# EFM32GG11B840F1024GL192 register map
File version: 4.0.0
CPU: CM4 r0p1, little endian, MPU, FPU, 3 interrupt priority bits
Registers are 32-bit, read-write, reset 0x0 unless marked. A register's access mark holds for its fields unless they carry their own. Offsets are from the block's base; [hi:lo] are bit positions; {n}, {i} and the like mark numbered series; 'fields as' and 'values as' point back to an identical list.

## SDIO
Base 0x400F1000
0x00 SDMASYSADDR — SDMA System Address Register
  [31:0] SDMASYSADDRARG — Physical SYS Memory ADDR Used for DMA Transfers or the Second Argument for the Auto CMD23
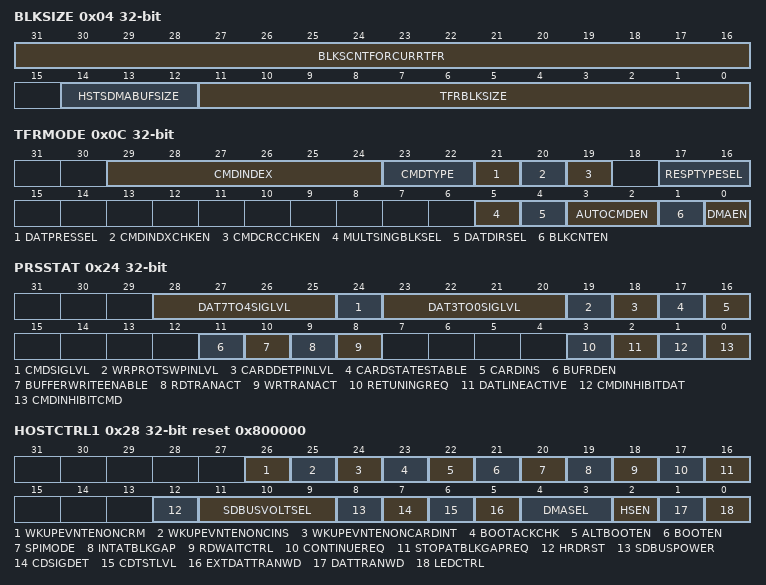
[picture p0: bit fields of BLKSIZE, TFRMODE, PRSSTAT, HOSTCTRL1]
0x04 BLKSIZE — Block Size and Block Count Register
  [31:16] BLKSCNTFORCURRTFR — Blocks Count for Current Transfer
    0=STOPCNT
  [14:12] HSTSDMABUFSIZE — Host SDMA Buffer Size
    0=SIZE4 (4KB(Detects A11 Carry out)); 1=SIZE8 (8KB(Detects A12 Carry out)); 2=SIZE16 (16KB(Detects A13 Carry out)); 3=SIZE32 (32KB(Detects A14 Carry out)); 4=SIZE64 (64KB(Detects A15 Carry out)); 5=SIZE128 (128KB(Detects A16 Carry out)); 6=SIZE256 (256KB(Detects A17 Carry out)); 7=SIZE512 (512KB(Detects A18 Carry out))
  [11:0] TFRBLKSIZE — Transfer Block Size, Specifies the Block Size for Block Data Transfers for CMD17, CMD18, CMD24, CMD25, and CMD53
    0=NOXFER
0x08 CMDARG1 — SD Command Argument Register
  [31:0] CMDARG1 — Command Argument 1
0x0C TFRMODE — Transfer Mode and Command Register
  [29:24] CMDINDEX — Command Index
  [23:22] CMDTYPE — Command Type
    0=NORMAL (Normal Command); 1=SUSPEND (Suspend command); 2=RESUME (Resume command); 3=ABORT (Abort command)
  [21] DATPRESSEL — Data Present Select
  [20] CMDINDXCHKEN — Command Index Check Enable
  [19] CMDCRCCHKEN — Command CRC Check Enable
  [17:16] RESPTYPESEL — Response Type Select
    0=NORESP; 1=RESP136 (RESP Length 136); 2=RESP48 (RESP Length 48); 3=BUSYAFTRESP (RESP Length 48 check busy after RESP)
  [5] MULTSINGBLKSEL — Multiple or Single Block Data Transfer Selection
  [4] DATDIRSEL — Data Transfer Direction Select
  [3:2] AUTOCMDEN — Auto Command Enable
    0=ACMDDISABLED (Auto CMD Disabled); 1=ACMD12EN (Auto CMD12 Enable); 2=ACMD23EN (Auto CMD23 Enable)
  [1] BLKCNTEN — Block Count Enable
  [0] DMAEN — DMA Enable
0x10 RESP0 ro — Response0 and Response1 Register
  [31:0] CMDRESP0 — Command Response 0
0x14 RESP2 ro — Response2 and Response3 Register
  [31:0] CMDRESP1 — Command Response 1
0x18 RESP4 ro — Response4 and Response5 Register
  [31:0] CMDRESP2 — Command Response 2
0x1C RESP6 ro — Response6 and Response7 Register
  [31:0] CMDRESP3 — Command Response 3
0x20 BUFDATPORT — Buffer Data Register
  [31:0] BUFDAT — Buffer Data
0x24 PRSSTAT ro — Present State Register
  [28:25] DAT7TO4SIGLVL — DAT[7:4] Line Signal Level
  [24] CMDSIGLVL — Command Line Signal Level
  [23:20] DAT3TO0SIGLVL — DAT[3:0] Line Signal Level
  [19] WRPROTSWPINLVL — Write Protect Switch Pin Level
  [18] CARDDETPINLVL — Card Detect Pin Level
  [17] CARDSTATESTABLE — Card State Stable Status
  [16] CARDINS — Card Inserted Status
  [11] BUFRDEN — Buffer Read Enable
  [10] BUFFERWRITEENABLE
  [9] RDTRANACT — Read Transfer Active
  [8] WRTRANACT — Write Transfer Active
  [3] RETUNINGREQ — Re-Tuning Request
  [2] DATLINEACTIVE
  [1] CMDINHIBITDAT — Command Inhibit (DAT)
  [0] CMDINHIBITCMD — Command Inhibit (CMD)
0x28 HOSTCTRL1 reset 0x800000 — Host Control1, Power, Block Gap and Wakeup-up Control Register
  [26] WKUPEVNTENONCRM — Wakeup Event Enable on SD Card Removal
  [25] WKUPEVNTENONCINS — Wakeup Event Enable on SD Card Insertion
  [24] WKUPEVNTENONCARDINT — Wakeup Event Enable on Card Interrupt
  [23] BOOTACKCHK — Boot Ack Check
  [22] ALTBOOTEN — Alternate Boot Enable
  [21] BOOTEN — Boot Enable
  [20] SPIMODE — SPI Mode Enable
  [19] INTATBLKGAP — Interrupt at Block Gap
  [18] RDWAITCTRL — Read Wait Control
  [17] CONTINUEREQ — Continue Request
  [16] STOPATBLKGAPREQ — Stop at Block Gap Request
  [12] HRDRST — Hardware Reset Signal
  [11:9] SDBUSVOLTSEL — SD Bus Voltage Select
    5=1P8V (Select 1.8V); 6=3P0V (Select 3.0V); 7=3P3V (Select 3.3V)
  [8] SDBUSPOWER
  [7] CDSIGDET — Card Detetct Signal Detection
  [6] CDTSTLVL — Card Detect Test Level
  [5] EXTDATTRANWD — Extended Data Transfer Width
  [4:3] DMASEL — DMA Select
    0=SDMA (SDMA selected); 1=ADMA1 (32-bit ADMA1 selected); 2=ADMA2 (32-bit ADMA2 selected); 3=64BITADMA2 (64-bit ADMA2 selected)
  [2] HSEN — High Speed Enable
  [1] DATTRANWD — Data Transfer Width 1-bit or 4-bit Mode
  [0] LEDCTRL — LED Control
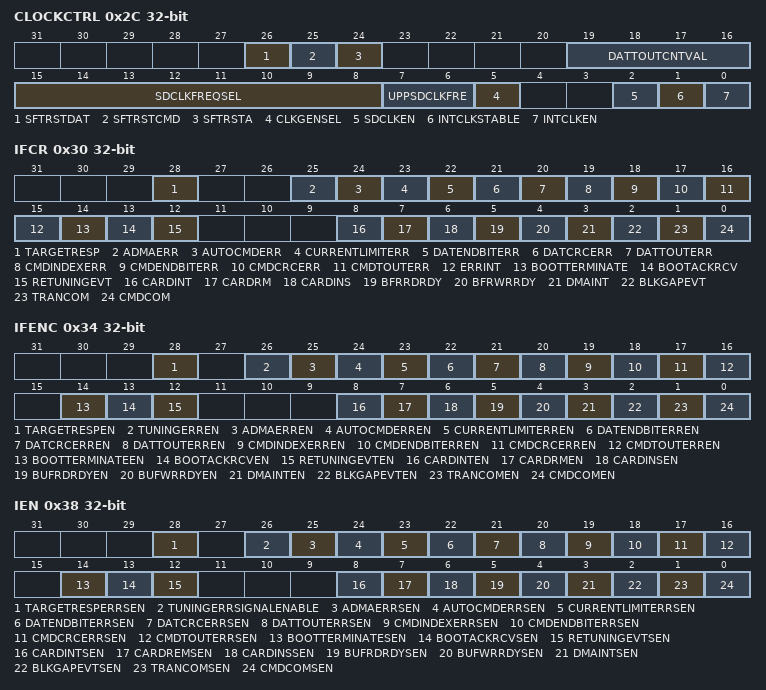
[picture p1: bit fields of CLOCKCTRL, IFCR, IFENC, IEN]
0x2C CLOCKCTRL — Clock Control, Timeout Control and Software Register
  [26] SFTRSTDAT — Software Reset for DAT Line
  [25] SFTRSTCMD — Software Reset for CMD Line
  [24] SFTRSTA — Software Reset for All
  [19:16] DATTOUTCNTVAL — Data Timeout Counter Value
  [15:8] SDCLKFREQSEL — SD_CLK Frequency Select
    0=NODIVISION
  [7:6] UPPSDCLKFRE — Upper Bits of SD_CLK Frequency Select
  [5] CLKGENSEL — Clock Generator Select
  [2] SDCLKEN — SDIO_CLK Pin Clock Enable
  [1] INTCLKSTABLE ro — Internal Clock Stable
  [0] INTCLKEN — Internal Clock Enable
0x30 IFCR — Normal and Error Interrupt Status Register
  [28] TARGETRESP — Specific Error STAT
  [25] ADMAERR — ADMA Error
  [24] AUTOCMDERR — Auto CMD Error
  [23] CURRENTLIMITERR — Current Limit Error
  [22] DATENDBITERR — Data End Bit Error
  [21] DATCRCERR — Data CRC Error
  [20] DATTOUTERR — Data Time-out Error
  [19] CMDINDEXERR — Command Index Error
  [18] CMDENDBITERR — Command End Bit Error
  [17] CMDCRCERR — CMD CRC Error
  [16] CMDTOUTERR — Command Timeout Error
  [15] ERRINT ro — Error Interrupt
  [14] BOOTTERMINATE — Boot Terminate Interrupt
  [13] BOOTACKRCV — Boot Ack Received
  [12] RETUNINGEVT ro — Re-Tunning Event
  [8] CARDINT ro — Card Interrupt
  [7] CARDRM — Card Removal
  [6] CARDINS — Card Insertion
  [5] BFRRDRDY — Buffer Read Ready
  [4] BFRWRRDY — Buffer Write Ready
  [3] DMAINT — DMA Interrupt
  [2] BLKGAPEVT — Block Gap Event
  [1] TRANCOM — Transfer Complete
  [0] CMDCOM — Command Complete
0x34 IFENC — Normal and Error Interrupt Status Enable Register
  [28] TARGETRESPEN — Target Response/Host Error Status Enable
  [26] TUNINGERREN — Tuning Error Status Enable
  [25] ADMAERREN — ADMA Error Status Enable
  [24] AUTOCMDERREN — Auto CMD12 Error Status Enable
  [23] CURRENTLIMITERREN — Current Limit Error Status Enable
  [22] DATENDBITERREN — Data End Bit Error Status Enable
  [21] DATCRCERREN — Data CRC Error Status Enable
  [20] DATTOUTERREN — Data Timeout Error Status Enable
  [19] CMDINDEXERREN — Command Index Error Status Enable
  [18] CMDENDBITERREN — Command End Bit Error Status Enable
  [17] CMDCRCERREN — Command CRC Error Status Enable
  [16] CMDTOUTERREN — Command Time-out Error Status Enable
  [14] BOOTTERMINATEEN — Boot Terminate Interrupt Signal Enable
  [13] BOOTACKRCVEN — Boot Ack Received Signal Enable
  [12] RETUNINGEVTEN — Re-Tunning Event Signal Enable
  [8] CARDINTEN — Card Interrupt Signal Enable
  [7] CARDRMEN — Card Removal Signal Enable
  [6] CARDINSEN — Card Insertion Signal Enable
  [5] BUFRDRDYEN — Buffer Read Ready Signal Enable
  [4] BUFWRRDYEN — Buffer Write Ready Signal Enable
  [3] DMAINTEN — DMA Interrupt Signal Enable
  [2] BLKGAPEVTEN — Block Gap Event Signal Enable
  [1] TRANCOMEN — Transfer Complete Signal Enable
  [0] CMDCOMEN — Command Complete Signal Enable
0x38 IEN — Normal and Error Interrupt Signal Enable Register
  [28] TARGETRESPERRSEN — Target Response Error Signal Enable
  [26] TUNINGERRSIGNALENABLE — Tuning Error Signal Enable
  [25] ADMAERRSEN — ADMA Error Signal Enable
  [24] AUTOCMDERRSEN — Auto CMD12 Error Signal Enable
  [23] CURRENTLIMITERRSEN — Current Limit Error Signal Enable
  [22] DATENDBITERRSEN — Data End Bit Error Signal Enable
  [21] DATCRCERRSEN — Data CRC Error Signal Enable
  [20] DATTOUTERRSEN — Data Timeout Error Signal Enable
  [19] CMDINDEXERRSEN — Command Index Error Signal Enable
  [18] CMDENDBITERRSEN — Command End Bit Error Signal Enable
  [17] CMDCRCERRSEN — Command CRC Error Signal Enable
  [16] CMDTOUTERRSEN — Command Timeout Error Signal Enable
  [14] BOOTTERMINATESEN — Boot Terminate Interrupt Signal Enable
  [13] BOOTACKRCVSEN — Boot Ack Received Signal Enable
  [12] RETUNINGEVTSEN — Re-Tuning Event Signal Enable
  [8] CARDINTSEN — Card Interrupt Signal Enable
  [7] CARDREMSEN — Card Removal Signal Enable
  [6] CARDINSSEN — Card Insertion Signal Enable
  [5] BUFRDRDYSEN — Buffer Read Ready Signal Enable
  [4] BUFWRRDYSEN — Buffer Write Ready Signal Enable
  [3] DMAINTSEN — DMA Interrupt Signal Enable
  [2] BLKGAPEVTSEN — Block Gap Event Signal Enable
  [1] TRANCOMSEN — Transfer Complete Signal Enable
  [0] CMDCOMSEN — Command Complete Signal Enable
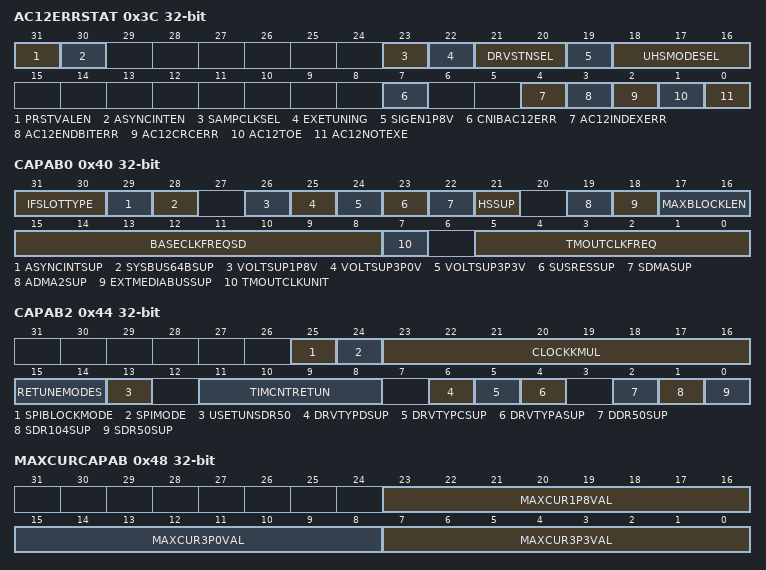
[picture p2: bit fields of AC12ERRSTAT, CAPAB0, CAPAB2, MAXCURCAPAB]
0x3C AC12ERRSTAT — AUTO CMD12 Error Status and Host Control2 Register
  [31] PRSTVALEN — Preset Value Enable
  [30] ASYNCINTEN — Asynchronous Interrupt Enable
  [23] SAMPCLKSEL — Sampling Clock Select
  [22] EXETUNING — Execute Tuning
  [21:20] DRVSTNSEL — Driver Strength Select
    0=TYPEB (Driver Type B is selected (Default)); 1=TYPEA (Driver Type A is selected); 2=TYPEC (Driver Type C is selected); 3=TYPED (Driver Type D is selected)
  [19] SIGEN1P8V — Voltage 1.8V Signal Enable
  [18:16] UHSMODESEL — UHS Mode Select
    0=SDR12; 1=SDR25; 2=SDR50; 3=SDR104; 4=DDR50
  [7] CNIBAC12ERR ro — Command Not Issued By Auto CMD12 Error
  [4] AC12INDEXERR ro — Auto CMD Index Error
  [3] AC12ENDBITERR ro — Auto CMD End Bit Error
  [2] AC12CRCERR ro — Auto CMD CRC Error
  [1] AC12TOE ro — Auto CMD12 Timeout Error
  [0] AC12NOTEXE ro — Auto CMD12 Not Executed
0x40 CAPAB0 ro — Capabilities Register to Hold Bits 31~0
  [31:30] IFSLOTTYPE — Interface Card Slot Type
    0=REMOVABLE (Removable Card Slot); 1=EMBEDDED (Only one non-removable device is conected to a SD bus slot); 2=SHARED (Can be set if Host controller supports Shared Bus CTRL register)
  [29] ASYNCINTSUP — Asynchronous Interrupt Support
  [28] SYSBUS64BSUP — System Bus 64-bit Support
  [26] VOLTSUP1P8V — Voltage Support 1.8V
  [25] VOLTSUP3P0V — Voltage Support 3.0V
  [24] VOLTSUP3P3V — Voltage Support 3.3V
  [23] SUSRESSUP — Suspend / Resume Support
  [22] SDMASUP — SDMA Support
  [21] HSSUP — High Speed Support
  [19] ADMA2SUP — ADMA2 Support
  [18] EXTMEDIABUSSUP — Extended Media Bus Support
  [17:16] MAXBLOCKLEN — Maximum Block Length
  [15:8] BASECLKFREQSD — Base Clock Frequency for SD_CLK
  [7] TMOUTCLKUNIT — Timeout Clock Unit
  [5:0] TMOUTCLKFREQ — Timeout Clock Frequency
0x44 CAPAB2 ro — Capabilities Register to Hold Bits 63~32
  [25] SPIBLOCKMODE — SPI Block Mode Support
  [24] SPIMODE — SPI Mode Support
  [23:16] CLOCKKMUL — Clock Multiplier
  [15:14] RETUNEMODES — Re-tuning Modes
  [13] USETUNSDR50 — Use Tuning for SDR50
  [11:8] TIMCNTRETUN — Timer Count for Re-Tuning
  [6] DRVTYPDSUP — Driver Type D Support
  [5] DRVTYPCSUP — Driver Type C Support
  [4] DRVTYPASUP — Driver Type a Support
  [2] DDR50SUP — DDR50 Support
  [1] SDR104SUP — SDR104 Support
  [0] SDR50SUP — SDR50 Support
0x48 MAXCURCAPAB ro — Maximum Current Capabilities Register
  [23:16] MAXCUR1P8VAL — Maximum Current for 1.8V
  [15:8] MAXCUR3P0VAL — Maximum Current for 3.0V
  [7:0] MAXCUR3P3VAL — Maximum Current for 3.3V
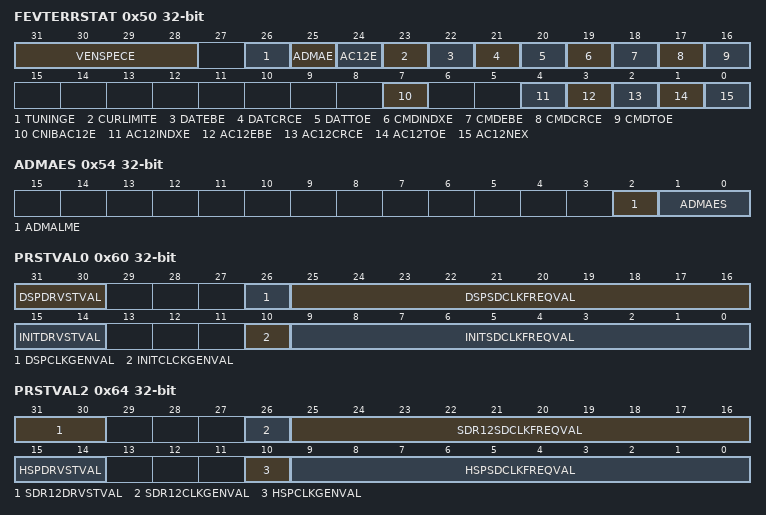
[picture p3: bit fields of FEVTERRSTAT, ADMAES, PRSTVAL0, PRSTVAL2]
0x50 FEVTERRSTAT — Force Event Register for Auto CMD Error Status
  [31:28] VENSPECE ro — Force Event for Vendox Specific Error Status
  [26] TUNINGE ro — Force Event for Tuning Errro
  [25] ADMAE — Force Event for ADMA Error
  [24] AC12E — Force Event for Auto CMD Error
  [23] CURLIMITE — Force Event for Current Limit Error
  [22] DATEBE — Force Event for Data End Bit Error
  [21] DATCRCE — Force Event for Data CRC Error
  [20] DATTOE — Force Event for Data Timeout Error
  [19] CMDINDXE — Force Event for Command Index Error
  [18] CMDEBE — Force Event for Command End Bit Error
  [17] CMDCRCE — Force Event for Command CRC Error
  [16] CMDTOE — Force Event for Command Timeout Error
  [7] CNIBAC12E — Force Event for Command Not Issued By Auto CMD12 Error
  [4] AC12INDXE — Force Event for Auto CMD Index Error
  [3] AC12EBE — Force Event for Auto CMD End Bit Error
  [2] AC12CRCE — Force Event for Auto CMD CRC Error
  [1] AC12TOE — Force Event for Auto CMD Timeout Error
  [0] AC12NEX — Force Event for Command Not Issued By Auto CM12 Not Executed
0x54 ADMAES ro — ADMA Error Status Register
  [2] ADMALME — ADMA Length Mismatch Error
  [1:0] ADMAES — ADMA Error State
0x58 ADSADDR — ADMA System Address Register
  [31:0] ADSADDR — ADMA System Address
0x60 PRSTVAL0 ro — Preset Value for Initialization and Default Speed Mode
  [31:30] DSPDRVSTVAL — Driver Strength Select Value for Default Speed
    values as AC12ERRSTAT.DRVSTNSEL
  [26] DSPCLKGENVAL — Clock Generator Select Value for Default Speed
  [25:16] DSPSDCLKFREQVAL — SD_CLK Frequency Select Value for Default Speed
  [15:14] INITDRVSTVAL — Driver Strength Select Value for Initialization
    values as AC12ERRSTAT.DRVSTNSEL
  [10] INITCLCKGENVAL — Clock Generator Select Value for Initialization
  [9:0] INITSDCLKFREQVAL — SD_CLK Frequency Select Value for Initialization
0x64 PRSTVAL2 ro — Preset Value for High Speed and SDR12 Modes
  [31:30] SDR12DRVSTVAL — Driver Strength Select Value for SDR12
    values as AC12ERRSTAT.DRVSTNSEL
  [26] SDR12CLKGENVAL — Clock Generator Select Value for SDR12
  [25:16] SDR12SDCLKFREQVAL — SD_CLK Frequency Select Value for SDR12
  [15:14] HSPDRVSTVAL — Driver Strength Select Value for High Speed
    values as AC12ERRSTAT.DRVSTNSEL
  [10] HSPCLKGENVAL — Clock Generator Select Value for High Speed
  [9:0] HSPSDCLKFREQVAL — SD_CLK Frequency Select Value for High Speed
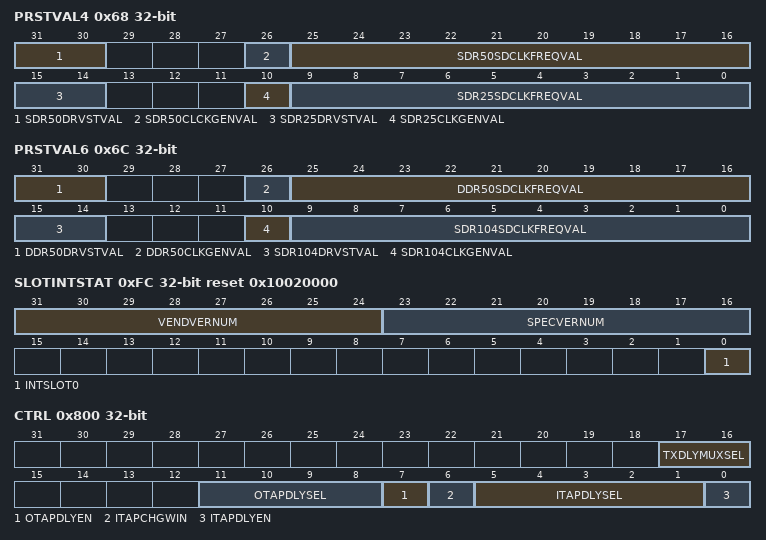
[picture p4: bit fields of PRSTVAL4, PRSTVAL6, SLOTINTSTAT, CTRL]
0x68 PRSTVAL4 ro — Preset Value for SDR25 and SDR50 Modes
  [31:30] SDR50DRVSTVAL — Driver Strength Select Value for SDR50
    values as AC12ERRSTAT.DRVSTNSEL
  [26] SDR50CLCKGENVAL — Clock Generator Select Value for SDR50
  [25:16] SDR50SDCLKFREQVAL — SD_CLK Frequency Select Value for SDR50
  [15:14] SDR25DRVSTVAL — Driver Strength Select Value for SDR25
    values as AC12ERRSTAT.DRVSTNSEL
  [10] SDR25CLKGENVAL — Clock Generator Select Value for SDR25
  [9:0] SDR25SDCLKFREQVAL — SD_CLK Frequency Select Value for SDR25
0x6C PRSTVAL6 ro — Preset Value for SDR104 and DDR50 Modes
  [31:30] DDR50DRVSTVAL — Driver Strength Select Value for DDR50
    values as AC12ERRSTAT.DRVSTNSEL
  [26] DDR50CLKGENVAL — Clock Generator Select Value for DDR50
  [25:16] DDR50SDCLKFREQVAL — SD_CLK Frequency Select Value for DDR50
  [15:14] SDR104DRVSTVAL — Driver Strength Select Value for SDR104
    values as AC12ERRSTAT.DRVSTNSEL
  [10] SDR104CLKGENVAL — Clock Generator Select Value for SDR104
  [9:0] SDR104SDCLKFREQVAL — SD_CLK Frequency Select Value for SDR104
0x70 BOOTTOCTRL — Boot Timeout Control Register
  [31:0] BOOTDATTOCNT — Boot Data Timeout Counter Value
0xFC SLOTINTSTAT ro reset 0x10020000 — Slot Interrupt Status Register
  [31:24] VENDVERNUM — Vendor Version Number
  [23:16] SPECVERNUM — Host Controller Compliant Spec Version Number
  [0] INTSLOT0 — Interrupt Signal for Slot#0
0x800 CTRL — Core Control Signals
  [17:16] TXDLYMUXSEL — TX Delay Mux Selection
  [11:8] OTAPDLYSEL — Selects One of 32 Taps on the SDIO_CLK Pin
  [7] OTAPDLYEN — Selective Tap Delay Line Enable on SDIO_CLK Pin
  [6] ITAPCHGWIN — Gating Signal for Tap Delay Change
  [5:1] ITAPDLYSEL — Selects One of 32 Taps on the Rxclk_in Line
  [0] ITAPDLYEN — Selective Tap Delay Line Enable on Rxclk_in
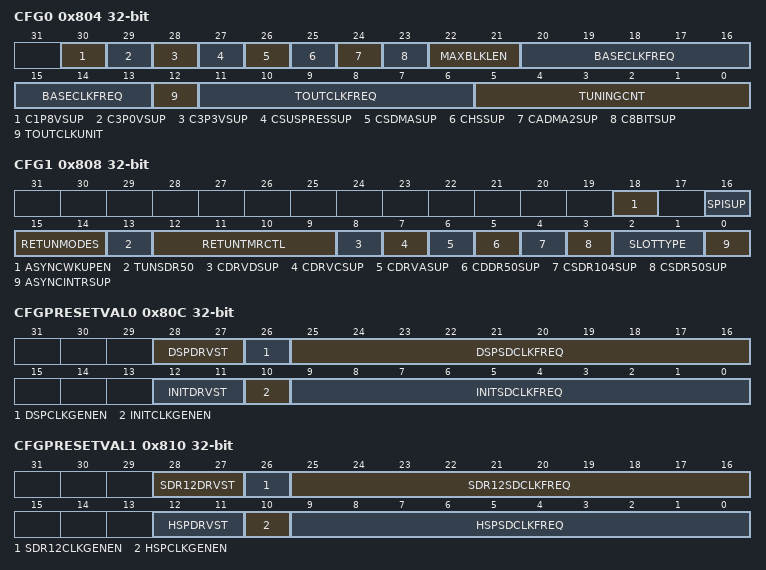
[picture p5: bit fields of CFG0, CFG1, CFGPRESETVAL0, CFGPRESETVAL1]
0x804 CFG0 — Core Configuration 0
  [30] C1P8VSUP — 1P8V Support
  [29] C3P0VSUP — 3P0V Support
  [28] C3P3VSUP — Core 3P3V Support
  [27] CSUSPRESSUP — Suspend/Resume Support
  [26] CSDMASUP — SDMA Mode Support
  [25] CHSSUP — High Speed Mode Support
  [24] CADMA2SUP — ADMA2 Mode Support
  [23] C8BITSUP — 8-bit Interface Support
  [22:21] MAXBLKLEN — MAX Block Length of Transfer
    0=512B (512 Bytes are Selected); 1=1024B (1024 Bytes are Selected); 2=2048B (2048 Bytes are Selected)
  [20:13] BASECLKFREQ — Base Clock Frequency for SD_CLK
  [12] TOUTCLKUNIT — Timeout Clock Unit in kHz or MHz
  [11:6] TOUTCLKFREQ — Timeout Clock Frequency
  [5:0] TUNINGCNT — Tuning Counter Value
0x808 CFG1 — Core Configuration 1
  [18] ASYNCWKUPEN — Asynchronous Wakeup Enable
  [16] SPISUP — SPI Support
  [15:14] RETUNMODES — Retuning Modes
  [13] TUNSDR50 — Tuning for SDR50
  [12:9] RETUNTMRCTL — Retuning Timer Control
  [8] CDRVDSUP — Support Type D Driver
  [7] CDRVCSUP — Support Type C Driver
  [6] CDRVASUP — Support Type a Driver
  [5] CDDR50SUP — Support DDR50
  [4] CSDR104SUP — Support SDR104
  [3] CSDR50SUP — Core Support SDR50
  [2:1] SLOTTYPE
    0=RMSDSLOT (Removable SD Card Slot); 1=EMSDSLOT (Embedded SD Card Slot); 2=SHBUSSLOT (Shared SD Card Slot)
  [0] ASYNCINTRSUP — Asynchronous Interrupt Support
0x80C CFGPRESETVAL0 — Core Configuration Preset Value 0
  [28:27] DSPDRVST — Default Speed Drive Strength
  [26] DSPCLKGENEN — Default Speed Clock Gen Enable
  [25:16] DSPSDCLKFREQ — Preset Value for Default Speed of SD_CLK
  [12:11] INITDRVST — Initial Drive Strength
  [10] INITCLKGENEN — Initial Clock Gen Enable
  [9:0] INITSDCLKFREQ — Initial SD_CLK Frequency
0x810 CFGPRESETVAL1 — Core Configuration Preset Value 1
  [28:27] SDR12DRVST — SDR12 Speed Drive Strength
  [26] SDR12CLKGENEN — SDR12 Speed Clock Gen Enable
  [25:16] SDR12SDCLKFREQ — Preset Value for SDR12 Speed of SD_CLK
  [12:11] HSPDRVST — High Speed SD Drive Strength
  [10] HSPCLKGENEN — High Speed SD_CLK Gen Enable
  [9:0] HSPSDCLKFREQ — High Speed SD_CLK Frequency
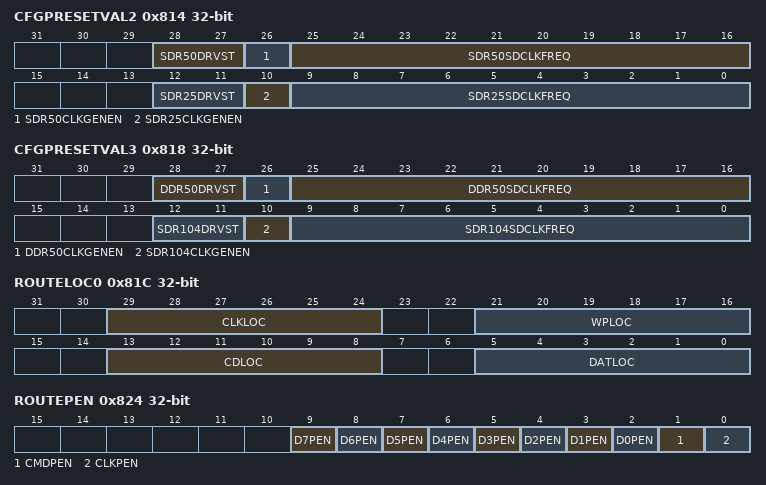
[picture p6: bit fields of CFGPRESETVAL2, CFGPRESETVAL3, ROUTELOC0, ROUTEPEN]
0x814 CFGPRESETVAL2 — Core Configuration Preset Value 2
  [28:27] SDR50DRVST — SDR50 Speed Drive Strength
  [26] SDR50CLKGENEN — SDR50 Speed Clock Gen Enable
  [25:16] SDR50SDCLKFREQ — Preset Value for SDR50 Speed of SD_CLK
  [12:11] SDR25DRVST — SDR25 SD Drive Strength
  [10] SDR25CLKGENEN — SDR25 SD_CLK Gen Enable
  [9:0] SDR25SDCLKFREQ — SDR25 SD_CLK Frequency
0x818 CFGPRESETVAL3 — Core Configuration Preset Value 3
  [28:27] DDR50DRVST — DDR50 Speed Drive Strength
  [26] DDR50CLKGENEN — DDR50 Speed Clock Gen Enable
  [25:16] DDR50SDCLKFREQ — Preset Value for DDR50 Speed of SD_CLK
  [12:11] SDR104DRVST — SDR104 SD Drive Strength
  [10] SDR104CLKGENEN — SDR104 SD_CLK Gen Enable
  [9:0] SDR104SDCLKFREQ — SDR104 SD_CLK Frequency
0x81C ROUTELOC0 — I/O LOCATION Register
  [29:24] CLKLOC — I/O Location for CLK
    0=LOC0 (Location 0); 1=LOC1 (Location 1)
  [21:16] WPLOC — I/O Location for WP
    {v}=LOC{v} (Location {v}) (v=0..3)
  [13:8] CDLOC — I/O Location for CD
    {v}=LOC{v} (Location {v}) (v=0..3)
  [5:0] DATLOC — I/O Location for D0-7 Pins
    0=LOC0 (Location 0); 1=LOC1 (Location 1)
0x820 ROUTELOC1 — I/O LOCATION Register
  [5:0] CMDLOC — I/O Location for CMD Pin
    0=LOC0 (Location 0); 1=LOC1 (Location 1)
0x824 ROUTEPEN — I/O LOCATION Enable Register
  [9] D7PEN — Data7 I/O Enable
  [8] D6PEN — Dat6 Enable
  [7] D5PEN — Dat5 Enable
  [n+2] D{n}PEN (n=0..4) — Dat{n} I/O Enable
  [1] CMDPEN — CMD I/O Enable
  [0] CLKPEN — CLK I/O Enable
